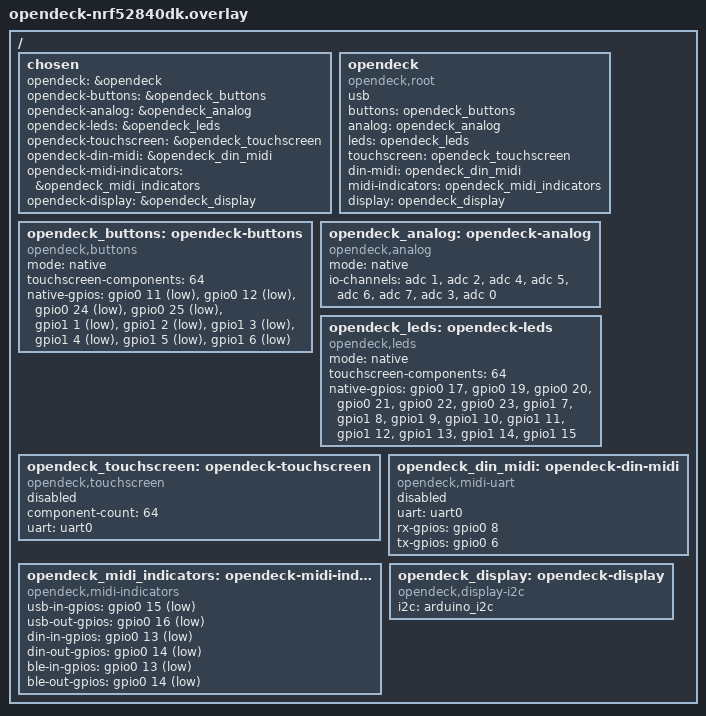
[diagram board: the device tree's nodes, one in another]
/ {
    chosen {
        opendeck = &opendeck;
        opendeck-buttons = &opendeck_buttons;
        opendeck-analog = &opendeck_analog;
        opendeck-leds = &opendeck_leds;
        opendeck-touchscreen = &opendeck_touchscreen;
        opendeck-din-midi = &opendeck_din_midi;
        opendeck-midi-indicators = &opendeck_midi_indicators;
        opendeck-display = &opendeck_display;
    };

    opendeck: opendeck {
        compatible = "opendeck,root";
        usb;
        buttons = <&opendeck_buttons>;
        analog = <&opendeck_analog>;
        leds = <&opendeck_leds>;
        touchscreen = <&opendeck_touchscreen>;
        din-midi = <&opendeck_din_midi>;
        midi-indicators = <&opendeck_midi_indicators>;
        display = <&opendeck_display>;
    };

    opendeck_buttons: opendeck-buttons {
        compatible = "opendeck,buttons";
        mode = "native";
        touchscreen-components = <64>;
        native-gpios =
            <&gpio0 11 GPIO_ACTIVE_LOW>,
            <&gpio0 12 GPIO_ACTIVE_LOW>,
            <&gpio0 24 GPIO_ACTIVE_LOW>,
            <&gpio0 25 GPIO_ACTIVE_LOW>,
            <&gpio1 1 GPIO_ACTIVE_LOW>,
            <&gpio1 2 GPIO_ACTIVE_LOW>,
            <&gpio1 3 GPIO_ACTIVE_LOW>,
            <&gpio1 4 GPIO_ACTIVE_LOW>,
            <&gpio1 5 GPIO_ACTIVE_LOW>,
            <&gpio1 6 GPIO_ACTIVE_LOW>;
    };

    opendeck_analog: opendeck-analog {
        compatible = "opendeck,analog";
        mode = "native";
        io-channels =
            <&adc 1>,
            <&adc 2>,
            <&adc 4>,
            <&adc 5>,
            <&adc 6>,
            <&adc 7>,
            <&adc 3>,
            <&adc 0>;
    };

    opendeck_leds: opendeck-leds {
        compatible = "opendeck,leds";
        mode = "native";
        touchscreen-components = <64>;
        native-gpios =
            <&gpio0 17 GPIO_ACTIVE_HIGH>,
            <&gpio0 19 GPIO_ACTIVE_HIGH>,
            <&gpio0 20 GPIO_ACTIVE_HIGH>,
            <&gpio0 21 GPIO_ACTIVE_HIGH>,
            <&gpio0 22 GPIO_ACTIVE_HIGH>,
            <&gpio0 23 GPIO_ACTIVE_HIGH>,
            <&gpio1 7 GPIO_ACTIVE_HIGH>,
            <&gpio1 8 GPIO_ACTIVE_HIGH>,
            <&gpio1 9 GPIO_ACTIVE_HIGH>,
            <&gpio1 10 GPIO_ACTIVE_HIGH>,
            <&gpio1 11 GPIO_ACTIVE_HIGH>,
            <&gpio1 12 GPIO_ACTIVE_HIGH>,
            <&gpio1 13 GPIO_ACTIVE_HIGH>,
            <&gpio1 14 GPIO_ACTIVE_HIGH>,
            <&gpio1 15 GPIO_ACTIVE_HIGH>;
    };

    opendeck_touchscreen: opendeck-touchscreen {
        disabled;
        compatible = "opendeck,touchscreen";
        component-count = <64>;
        uart = <&uart0>;
    };

    opendeck_din_midi: opendeck-din-midi {
        disabled;
        compatible = "opendeck,midi-uart";
        uart = <&uart0>;
        rx-gpios = <&gpio0 8 GPIO_ACTIVE_HIGH>;
        tx-gpios = <&gpio0 6 GPIO_ACTIVE_HIGH>;
    };

    opendeck_midi_indicators: opendeck-midi-indicators {
        compatible = "opendeck,midi-indicators";
        usb-in-gpios = <&gpio0 15 GPIO_ACTIVE_LOW>;
        usb-out-gpios = <&gpio0 16 GPIO_ACTIVE_LOW>;
        din-in-gpios = <&gpio0 13 GPIO_ACTIVE_LOW>;
        din-out-gpios = <&gpio0 14 GPIO_ACTIVE_LOW>;
        ble-in-gpios = <&gpio0 13 GPIO_ACTIVE_LOW>;
        ble-out-gpios = <&gpio0 14 GPIO_ACTIVE_LOW>;
    };

    opendeck_display: opendeck-display {
        compatible = "opendeck,display-i2c";
        i2c = <&arduino_i2c>;
    };
};
